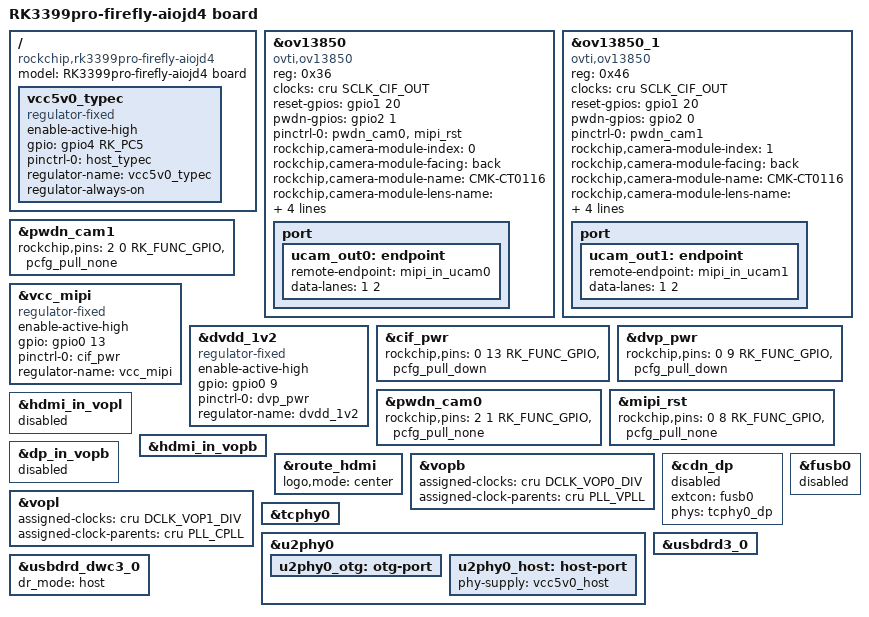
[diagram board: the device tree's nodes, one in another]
/*
 * Copyright (c) 2016 Fuzhou Rockchip Electronics Co., Ltd
 *
 * This file is dual-licensed: you can use it either under the terms
 * of the GPL or the X11 license, at your option. Note that this dual
 * licensing only applies to this file, and not this project as a
 * whole.
 *
 *  a) This file is free software; you can redistribute it and/or
 *     modify it under the terms of the GNU General Public License as
 *     published by the Free Software Foundation; either version 2 of the
 *     License, or (at your option) any later version.
 *                                                                                                                                             
 *     This file is distributed in the hope that it will be useful,
 *     but WITHOUT ANY WARRANTY; without even the implied warranty of
 *     MERCHANTABILITY or FITNESS FOR A PARTICULAR PURPOSE.  See the
 *     GNU General Public License for more details.
 *
 * Or, alternatively,
 *
 *  b) Permission is hereby granted, free of charge, to any person
 *     obtaining a copy of this software and associated documentation
 *     files (the "Software"), to deal in the Software without
 *     restriction, including without limitation the rights to use,
 *     copy, modify, merge, publish, distribute, sublicense, and/or
 *     sell copies of the Software, and to permit persons to whom the
 *     Software is furnished to do so, subject to the following
 *     conditions:
 *
 *     The above copyright notice and this permission notice shall be
 *     included in all copies or substantial portions of the Software.
 *
 *     THE SOFTWARE IS PROVIDED "AS IS", WITHOUT WARRANTY OF ANY KIND,
 *     EXPRESS OR IMPLIED, INCLUDING BUT NOT LIMITED TO THE WARRANTIES
 *     OF MERCHANTABILITY, FITNESS FOR A PARTICULAR PURPOSE AND
 *     NONINFRINGEMENT. IN NO EVENT SHALL THE AUTHORS OR COPYRIGHT
 *     HOLDERS BE LIABLE FOR ANY CLAIM, DAMAGES OR OTHER LIABILITY,
 *     WHETHER IN AN ACTION OF CONTRACT, TORT OR OTHERWISE, ARISING
 *     FROM, OUT OF OR IN CONNECTION WITH THE SOFTWARE OR THE USE OR
 *     OTHER DEALINGS IN THE SOFTWARE.
 */

/dts-v1/;
#include "rk3399pro-firefly-port.dtsi"

/ {
	model = "RK3399pro-firefly-aiojd4 board";
	compatible = "rockchip,rk3399pro-firefly-aiojd4", "rockchip,rk3399pro";

    vcc5v0_typec: vcc5v0_typec {
            compatible = "regulator-fixed";
            enable-active-high;
            gpio = <&gpio4 RK_PC5 GPIO_ACTIVE_HIGH>;
            pinctrl-names = "default";
            pinctrl-0 = <&host_typec>;
            regulator-name = "vcc5v0_typec";
            regulator-always-on;
    };

    ///delete-node/ ov13850@36;
    ///delete-node/ ov13850@46;



};

&ov13850 {
    compatible = "ovti,ov13850";
    status = "okay";
    reg = <0x36>;
    clocks = <&cru SCLK_CIF_OUT>;
    clock-names = "xvclk";

    /* conflict with csi-ctl-gpios */
    reset-gpios = <&gpio1 20 GPIO_ACTIVE_HIGH>;  /*GPIO1_C4 MIP_RST*/
    pwdn-gpios = <&gpio2 1 GPIO_ACTIVE_HIGH>;   /*GPIO2_A1/MIPI_PDN1_H VSYNC*/
    pinctrl-names = "rockchip,camera_default", "rockchip,camera_sleep";
    //pinctrl-0 = <&cif_clkout>;
    pinctrl-0 = <&pwdn_cam0 &mipi_rst>;
    /delete-property/ pinctrl-1;
    // pinctrl-1 = <&cam0_default_pins>;
    // pinctrl-2 = <&cam0_sleep_pins>;

    rockchip,camera-module-index = <0>;
    rockchip,camera-module-facing = "back";
    rockchip,camera-module-name = "CMK-CT0116";
    rockchip,camera-module-lens-name = "Largan-50013A1";

    avdd-supply = <&vcc_mipi>; /* GPIO0_B5 CIF_PWR  AGND*/                                                                                                                                              
    dovdd-supply = <&vcc_mipi>; /* GPIO0_B5 CIF_PWR  AGND */
    dvdd-supply = <&dvdd_1v2>; /* GPIO0_B1 DVP_PWR DVDD_1V2 */

    port {
        ucam_out0: endpoint {
            remote-endpoint = <&mipi_in_ucam0>;
            data-lanes = <1 2>;
        };
    };
};


&ov13850_1 {
    compatible = "ovti,ov13850";
    status = "okay";
    reg = <0x46>;
    clocks = <&cru SCLK_CIF_OUT>;
    clock-names = "xvclk";

    /* conflict with csi-ctl-gpios */
    reset-gpios = <&gpio1 20 GPIO_ACTIVE_HIGH>;  /*GPIO1_C4 MIP_RST*/
    pwdn-gpios = <&gpio2 0 GPIO_ACTIVE_HIGH>;   /*GPIO2_A0/MIPI_PDN1_H VSYNC*/
    pinctrl-names = "rockchip,camera_default", "rockchip,camera_sleep";
    pinctrl-0 = <&pwdn_cam1>;
    //pinctrl-0 = <&cif_clkout>;
    // pinctrl-1 = <&cam0_default_pins>;
    // pinctrl-2 = <&cam0_sleep_pins>;
    rockchip,camera-module-index = <1>;
    rockchip,camera-module-facing = "back";
    rockchip,camera-module-name = "CMK-CT0116";
    rockchip,camera-module-lens-name = "Largan-50013A1";

    avdd-supply = <&vcc_mipi>; /* GPIO0_B5 CIF_PWR  AGND*/                                                                                                                                              
    dovdd-supply = <&vcc_mipi>; /* GPIO0_B5 CIF_PWR  AGND */
    dvdd-supply = <&dvdd_1v2>; /* GPIO0_B1 DVP_PWR DVDD_1V2 */


    port {
        ucam_out1: endpoint {
            remote-endpoint = <&mipi_in_ucam1>;
            data-lanes = <1 2>;
        };
    };
};


&pwdn_cam1 {
    rockchip,pins =
        <2 0 RK_FUNC_GPIO &pcfg_pull_none>;
};


&vcc_mipi {
    compatible = "regulator-fixed";
    enable-active-high;
    gpio = <&gpio0 13 GPIO_ACTIVE_HIGH>;
    pinctrl-names = "default";
    pinctrl-0 = <&cif_pwr>;
    regulator-name = "vcc_mipi";
    status = "okay";
};


&dvdd_1v2 {
    compatible = "regulator-fixed";
    enable-active-high;
    gpio = <&gpio0 9 GPIO_ACTIVE_HIGH>;
    pinctrl-names = "default";
    pinctrl-0 = <&dvp_pwr>;
    regulator-name = "dvdd_1v2";
    status = "okay";
};

&cif_pwr {
    rockchip,pins = <0 13 RK_FUNC_GPIO &pcfg_pull_down>;
};

&dvp_pwr {
    rockchip,pins = <0 9 RK_FUNC_GPIO &pcfg_pull_down>;
};




&pwdn_cam0 {
    rockchip,pins =
        <2 1 RK_FUNC_GPIO &pcfg_pull_none>;
};

&mipi_rst {
    rockchip,pins =
        <0 8 RK_FUNC_GPIO &pcfg_pull_none>;
};


/*
&hdmi_dp_sound {
	status = "okay";
};
*/
&hdmi_in_vopl {
	status = "disabled";
};

&hdmi_in_vopb {
	status = "okay";
};

&dp_in_vopb {
	status = "disabled";
};

&route_hdmi {
        status = "okay";
        logo,mode = "center";
};

&vopb {
    assigned-clocks = <&cru DCLK_VOP0_DIV>;
    assigned-clock-parents = <&cru PLL_VPLL>;
};
&vopl {
    assigned-clocks = <&cru DCLK_VOP1_DIV>;
    assigned-clock-parents = <&cru PLL_CPLL>;
};

// Disable DP Display

&cdn_dp {
	status = "disabled";
	extcon = <&fusb0>;
	phys = <&tcphy0_dp>;
};

&fusb0 {
    status = "disabled";
};

&tcphy0 {
    /delete-property/ extcon;
    status = "okay";
};

&u2phy0 {
	status = "okay";
	/delete-property/ extcon;

	u2phy0_otg: otg-port {
		    status = "okay";
	    };  

	u2phy0_host: host-port {
		     phy-supply = <&vcc5v0_host>;
		     status = "okay";
	     };
};

&usbdrd3_0 {
    status = "okay";
    /delete-property/ extcon;
};

&usbdrd_dwc3_0 {
        status = "okay";
       dr_mode = "host";
 };



